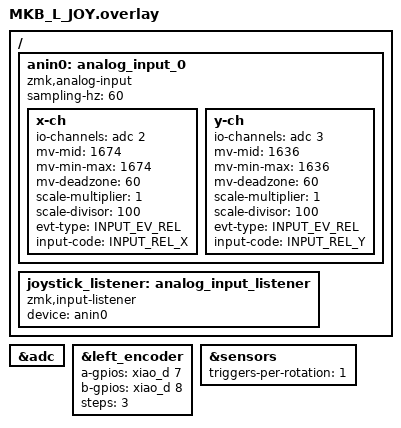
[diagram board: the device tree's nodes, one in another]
#include <zephyr/dt-bindings/input/input-event-codes.h>
#include <input/processors.dtsi>
#include <dt-bindings/zmk/input_transform.h>
#include <dt-bindings/zmk/keys.h>

&adc {
	status = "okay";
};

&left_encoder {
    a-gpios = <&xiao_d 7 (GPIO_ACTIVE_HIGH | GPIO_PULL_UP)>;
    b-gpios = <&xiao_d 8 (GPIO_ACTIVE_HIGH | GPIO_PULL_UP)>;
    steps = <3>;
    status = "okay";
};

&sensors {
    triggers-per-rotation = <1>;
};

/ {
    anin0: analog_input_0 {
        compatible = "zmk,analog-input";
        sampling-hz = <60>;
        x-ch {
            io-channels = <&adc 2>;
            mv-mid = <1674>;
            mv-min-max = <1674>;
            mv-deadzone = <60>;
            scale-multiplier = <1>;
            scale-divisor = <100>;
            // invert;
            evt-type = <INPUT_EV_REL>;
            input-code = <INPUT_REL_X>;
        };
        y-ch {
            io-channels = <&adc 3>;
            mv-mid = <1636>;
            mv-min-max = <1636>;
            mv-deadzone = <60>;
            scale-multiplier = <1>;
            scale-divisor = <100>;
            // invert;
            evt-type = <INPUT_EV_REL>;
            input-code = <INPUT_REL_Y>;
        };
    };

    joystick_listener: analog_input_listener {
        status = "okay";
        compatible = "zmk,input-listener";
        device = <&anin0>;
    };
};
